AUTOSAR XML (schema 4-0-3)
package /ComponentTypes
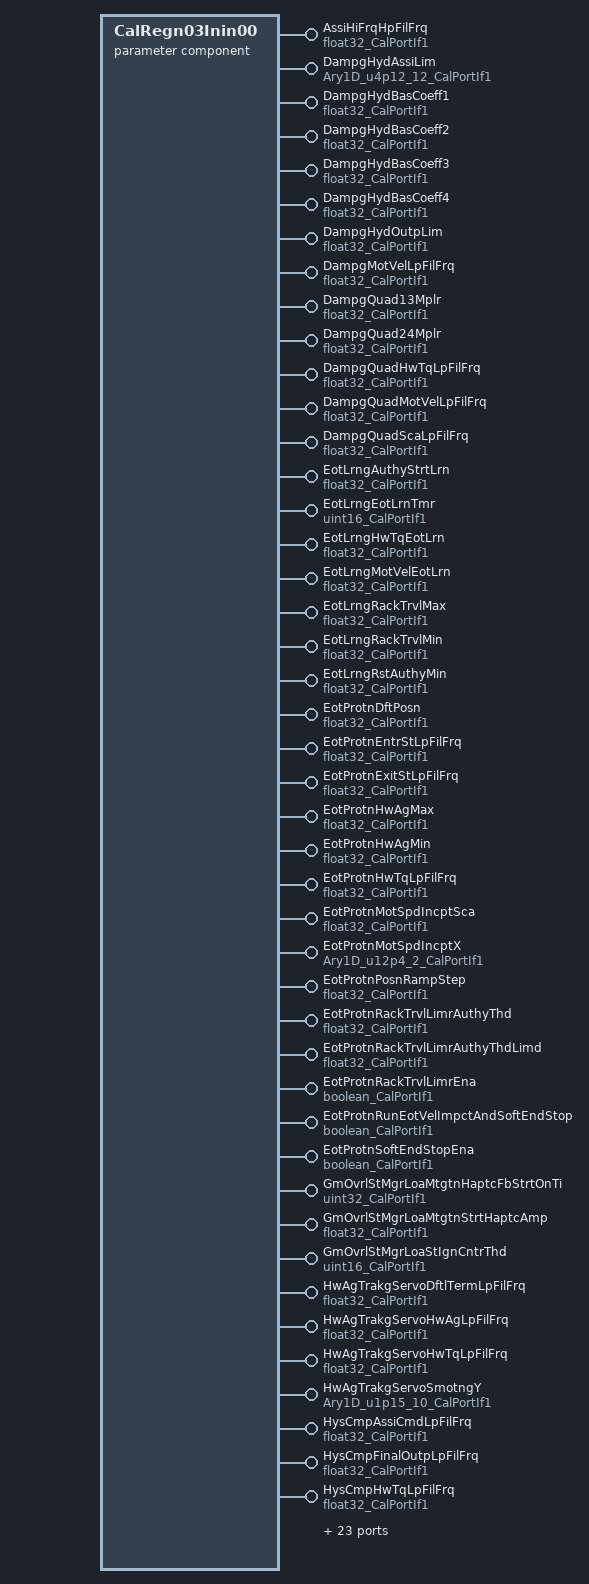
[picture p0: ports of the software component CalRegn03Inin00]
  parameter sw component type CalRegn03Inin00
    70 x provide port:
      AssiHiFrqHpFilFrq: parameter-provide-com-spec{init-value=15, parameter=Val}, provided-interface=float32_CalPortIf1
      DampgHydAssiLim: parameter-provide-com-spec{init-value=12 x 36045, parameter=Ary1D}, provided-interface=Ary1D_u4p12_12_CalPortIf1
      DampgHydBasCoeff1: parameter-provide-com-spec{init-value=0.0005, parameter=Val}, provided-interface=float32_CalPortIf1
      DampgHydBasCoeff2: parameter-provide-com-spec{init-value=2e-05, parameter=Val}, provided-interface=float32_CalPortIf1
      DampgHydBasCoeff3: parameter-provide-com-spec{init-value=0.006, parameter=Val}, provided-interface=float32_CalPortIf1
      DampgHydBasCoeff4: parameter-provide-com-spec{init-value=9e-06, parameter=Val}, provided-interface=float32_CalPortIf1
      DampgHydOutpLim: parameter-provide-com-spec{init-value=0, parameter=Val}, provided-interface=float32_CalPortIf1
      DampgMotVelLpFilFrq: parameter-provide-com-spec{init-value=15, parameter=Val}, provided-interface=float32_CalPortIf1
      DampgQuad13Mplr: parameter-provide-com-spec{init-value=1, parameter=Val}, provided-interface=float32_CalPortIf1
      DampgQuad24Mplr: parameter-provide-com-spec{init-value=1, parameter=Val}, provided-interface=float32_CalPortIf1
      DampgQuadHwTqLpFilFrq: parameter-provide-com-spec{init-value=15, parameter=Val}, provided-interface=float32_CalPortIf1
      DampgQuadMotVelLpFilFrq: parameter-provide-com-spec{init-value=15, parameter=Val}, provided-interface=float32_CalPortIf1
      DampgQuadScaLpFilFrq: parameter-provide-com-spec{init-value=15, parameter=Val}, provided-interface=float32_CalPortIf1
      EotLrngAuthyStrtLrn: parameter-provide-com-spec{init-value=1, parameter=Val}, provided-interface=float32_CalPortIf1
      EotLrngEotLrnTmr: parameter-provide-com-spec{init-value=100, parameter=Val}, provided-interface=uint16_CalPortIf1
      EotLrngHwTqEotLrn: parameter-provide-com-spec{init-value=2, parameter=Val}, provided-interface=float32_CalPortIf1
      EotLrngMotVelEotLrn: parameter-provide-com-spec{init-value=50, parameter=Val}, provided-interface=float32_CalPortIf1
      EotLrngRackTrvlMax: parameter-provide-com-spec{init-value=800, parameter=Val}, provided-interface=float32_CalPortIf1
      EotLrngRackTrvlMin: parameter-provide-com-spec{init-value=400, parameter=Val}, provided-interface=float32_CalPortIf1
      EotLrngRstAuthyMin: parameter-provide-com-spec{init-value=1, parameter=Val}, provided-interface=float32_CalPortIf1
      EotProtnDftPosn: parameter-provide-com-spec{init-value=100, parameter=Val}, provided-interface=float32_CalPortIf1
      EotProtnEntrStLpFilFrq: parameter-provide-com-spec{init-value=30, parameter=Val}, provided-interface=float32_CalPortIf1
      EotProtnExitStLpFilFrq: parameter-provide-com-spec{init-value=5, parameter=Val}, provided-interface=float32_CalPortIf1
      EotProtnHwAgMax: parameter-provide-com-spec{init-value=600, parameter=Val}, provided-interface=float32_CalPortIf1
      EotProtnHwAgMin: parameter-provide-com-spec{init-value=550, parameter=Val}, provided-interface=float32_CalPortIf1
      EotProtnHwTqLpFilFrq: parameter-provide-com-spec{init-value=30, parameter=Val}, provided-interface=float32_CalPortIf1
      EotProtnMotSpdIncptSca: parameter-provide-com-spec{init-value=0.02, parameter=Val}, provided-interface=float32_CalPortIf1
      EotProtnMotSpdIncptX: parameter-provide-com-spec{init-value=[800, 400], parameter=Ary1D}, provided-interface=Ary1D_u12p4_2_CalPortIf1
      EotProtnPosnRampStep: parameter-provide-com-spec{init-value=3, parameter=Val}, provided-interface=float32_CalPortIf1
      EotProtnRackTrvlLimrAuthyThd: parameter-provide-com-spec{init-value=1, parameter=Val}, provided-interface=float32_CalPortIf1
      EotProtnRackTrvlLimrAuthyThdLimd: parameter-provide-com-spec{init-value=1, parameter=Val}, provided-interface=float32_CalPortIf1
      EotProtnRackTrvlLimrEna: parameter-provide-com-spec{init-value=0, parameter=Logl}, provided-interface=boolean_CalPortIf1
      EotProtnRunEotVelImpctAndSoftEndStop: parameter-provide-com-spec{init-value=0, parameter=Logl}, provided-interface=boolean_CalPortIf1
      EotProtnSoftEndStopEna: parameter-provide-com-spec{init-value=0, parameter=Logl}, provided-interface=boolean_CalPortIf1
      GmOvrlStMgrLoaMtgtnHaptcFbStrtOnTi: parameter-provide-com-spec{init-value=2000, parameter=Val}, provided-interface=uint32_CalPortIf1
      GmOvrlStMgrLoaMtgtnStrtHaptcAmp: parameter-provide-com-spec{init-value=0.2, parameter=Val}, provided-interface=float32_CalPortIf1
      GmOvrlStMgrLoaStIgnCntrThd: parameter-provide-com-spec{init-value=20, parameter=Val}, provided-interface=uint16_CalPortIf1
      HwAgTrakgServoDftlTermLpFilFrq: parameter-provide-com-spec{init-value=10, parameter=Val}, provided-interface=float32_CalPortIf1
      HwAgTrakgServoHwAgLpFilFrq: parameter-provide-com-spec{init-value=2, parameter=Val}, provided-interface=float32_CalPortIf1
      HwAgTrakgServoHwTqLpFilFrq: parameter-provide-com-spec{init-value=2, parameter=Val}, provided-interface=float32_CalPortIf1
      HwAgTrakgServoSmotngY: parameter-provide-com-spec{init-value=[0, 786, 3113, 6750, 11305, 21463, 26018, 29655, 31982, 32768], parameter=Ary1D}, provided-interface=Ary1D_u1p15_10_CalPortIf1
      HysCmpAssiCmdLpFilFrq: parameter-provide-com-spec{init-value=50, parameter=Val}, provided-interface=float32_CalPortIf1
      HysCmpFinalOutpLpFilFrq: parameter-provide-com-spec{init-value=50, parameter=Val}, provided-interface=float32_CalPortIf1
      HysCmpHwTqLpFilFrq: parameter-provide-com-spec{init-value=50, parameter=Val}, provided-interface=float32_CalPortIf1
      InertiaCmpVelMotInertia: parameter-provide-com-spec{init-value=0.001, parameter=Val}, provided-interface=float32_CalPortIf1
      InertiaCmpVelNotchFilStruct: parameter-provide-com-spec=Rec, provided-interface=FilNotchGainRec1_CalPortIf1
      InertiaCmpVelTqSnsrVelFilFrq: parameter-provide-com-spec{init-value=20, parameter=Val}, provided-interface=float32_CalPortIf1
      PullCmpActvYawRateFilFrq: parameter-provide-com-spec{init-value=3, parameter=Val}, provided-interface=float32_CalPortIf1
      PwrpkCmpbltyChkGearId: parameter-provide-com-spec{init-value=0, parameter=Val}, provided-interface=uint8_CalPortIf1
      RtnHwAuthyScaX: parameter-provide-com-spec{init-value=[0, 128, 192, 256], parameter=Ary1D}, provided-interface=Ary1D_u8p8_4_CalPortIf1
      RtnHwAuthyScaY: parameter-provide-com-spec{init-value=[0, 0, 0, 128], parameter=Ary1D}, provided-interface=Ary1D_u9p7_4_CalPortIf1
      RtnHwAuthySlew: parameter-provide-com-spec{init-value=0.5, parameter=Val}, provided-interface=float32_CalPortIf1
      RtnOffsRng: parameter-provide-com-spec{init-value=17, parameter=Val}, provided-interface=float32_CalPortIf1
      RtnOffsSlew: parameter-provide-com-spec{init-value=0.04, parameter=Val}, provided-interface=float32_CalPortIf1
      StabyCmpAssiScaBlndX: parameter-provide-com-spec{init-value=[16384, 32768], parameter=Ary1D}, provided-interface=Ary1D_u2p14_2_CalPortIf1
      StabyCmpAssiScaBlndY: parameter-provide-com-spec{init-value=[0, 0], parameter=Ary1D}, provided-interface=Ary1D_u2p14_2_CalPortIf1
      StabyCmpHwTqLpFilFrq: parameter-provide-com-spec{init-value=30, parameter=Val}, provided-interface=float32_CalPortIf1
      StabyCmpNotchFil{1..4}Struct: parameter-provide-com-spec=Rec, provided-interface=FilNotchGainRec1_CalPortIf1
      StabyCmpNotchFilBlnd04Y: parameter-provide-com-spec{init-value=6 x 5 x 16384, parameter=Ary2D}, provided-interface=Ary2D_u2p14_6_5_CalPortIf1
      StabyCmpNotchFilBlnd34TqX: parameter-provide-com-spec{init-value=[5 x 0, 5 x 512, 5 x 768, 5 x 1024, 5 x 1536, 5 x 2048], parameter=Ary2D}, provided-interface=Ary2D_u8p8_6_5_CalPortIf1
      StabyCmpNotchFilBlnd34Y: parameter-provide-com-spec{init-value=6 x 5 x 0, parameter=Ary2D}, provided-interface=Ary2D_u2p14_6_5_CalPortIf1
      SysGlbPrmSysKineRat: parameter-provide-com-spec{init-value=22, parameter=Val}, provided-interface=float32_CalPortIf1
      SysGlbPrmSysTqRat: parameter-provide-com-spec{init-value=20, parameter=Val}, provided-interface=float32_CalPortIf1
      WhlImbRejctnBlndCmdMgnLp1FilFrq: parameter-provide-com-spec{init-value=5, parameter=Val}, provided-interface=float32_CalPortIf1
      WhlImbRejctnBlndCmdMgnLp2FilFrq: parameter-provide-com-spec{init-value=5, parameter=Val}, provided-interface=float32_CalPortIf1
      WhlImbRejctnDistbnMgnLpFil: parameter-provide-com-spec{init-value=0.5, parameter=Val}, provided-interface=float32_CalPortIf1
      WhlImbRejctnWhlSpdLpFil: parameter-provide-com-spec{init-value=3, parameter=Val}, provided-interface=float32_CalPortIf1
